# AST1060 register map
File version: 1.0
CPU: CM4 r0p1, little endian, MPU, FPU, 4 interrupt priority bits, 256 interrupts
Registers are 32-bit, read-write, reset 0x0 unless marked. A register's access mark holds for its fields unless they carry their own. Offsets are from the block's base; [hi:lo] are bit positions; {n}, {i} and the like mark numbered series; 'fields as' and 'values as' point back to an identical list.

## i2c
Base 0x7E7B0080
Same registers: i2c{n} {0x7E7B0080+0x80*n} (n=1..13)
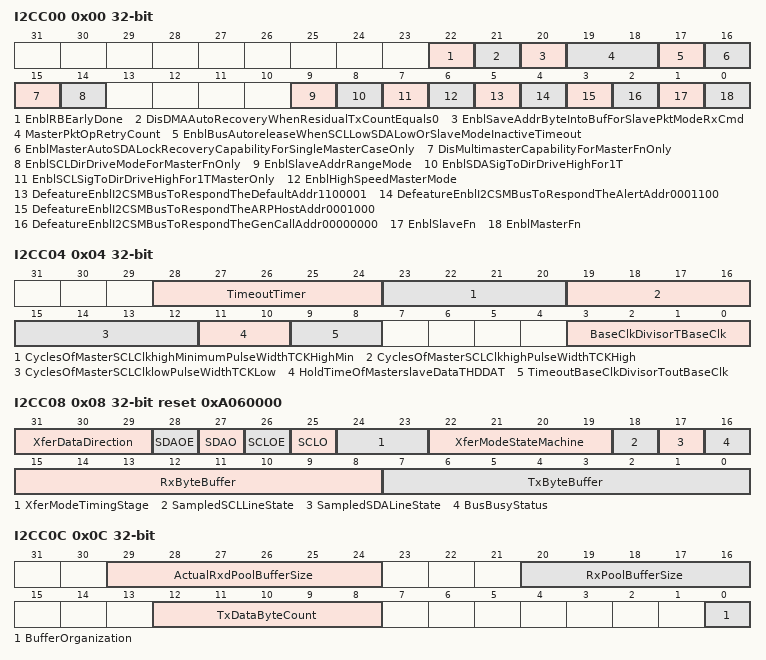
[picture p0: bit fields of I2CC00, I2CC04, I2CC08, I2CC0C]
0x00 I2CC00 (reset mask 0x3FC3FF) — Master/Slave Function Control Register
  [22] EnblRBEarlyDone — Enable RB early done
  [21] DisDMAAutoRecoveryWhenResidualTxCountEquals0 — DisableDMA AutoRecovery when residual Tx Count equals 0
  [20] EnblSaveAddrByteIntoBufForSlavePktModeRxCmd — Enable save address byte into buffer for Slave Packet mode receive command
  [19:18] MasterPktOpRetryCount — Master packet operation retry count
  [17] EnblBusAutoreleaseWhenSCLLowSDALowOrSlaveModeInactiveTimeout — Enable bus auto-release when SCL low, SDA low, or slave mode inactive timeout
  [16] EnblMasterAutoSDALockRecoveryCapabilityForSingleMasterCaseOnly — Enable master auto SDA lock recovery capability (for single master case only)
  [15] DisMultimasterCapabilityForMasterFnOnly — Disable multi-master capability (for master function only)
  [14] EnblSCLDirDriveModeForMasterFnOnly — Enable SCL direct drive mode (for master function only)
  [9] EnblSlaveAddrRangeMode — Enable slave address range mode
  [8] EnblSDASigToDirDriveHighFor1T — Enable SDA signal to direct drive high for 1T
  [7] EnblSCLSigToDirDriveHighFor1TMasterOnly — Enable SCL signal to direct drive high for 1T (Master Only)
  [6] EnblHighSpeedMasterMode — Enable High Speed master mode
  [5] DefeatureEnblI2CSMBusToRespondTheDefaultAddr1100001 — defeatureEnable I2C/SMBus to respond the Default Address (1100_001)
  [4] DefeatureEnblI2CSMBusToRespondTheAlertAddr0001100 — defeatureEnable I2C/SMBus to respond the Alert Address (0001_100)
  [3] DefeatureEnblI2CSMBusToRespondTheARPHostAddr0001000 — defeatureEnable I2C/SMBus to respond the ARP Host Address (0001_000)
  [2] DefeatureEnblI2CSMBusToRespondTheGenCallAddr00000000 — defeatureEnable I2C/SMBus to respond the General Call Address (0000_0000)
  [1] EnblSlaveFn — Enable slave function
  [0] EnblMasterFn — Enable master function
0x04 I2CC04 — Master/Slave Clock and AC Timing Control Register \#1
  [28:24] TimeoutTimer
  [23:20] CyclesOfMasterSCLClkhighMinimumPulseWidthTCKHighMin — Cycles of master SCL clock-high minimum pulse width (tCKHighMin)
  [19:16] CyclesOfMasterSCLClkhighPulseWidthTCKHigh — Cycles of master SCL clock-high pulse width (tCKHigh)
  [15:12] CyclesOfMasterSCLClklowPulseWidthTCKLow — Cycles of master SCL clock-low pulse width (tCKLow)
  [11:10] HoldTimeOfMasterslaveDataTHDDAT
  [9:8] TimeoutBaseClkDivisorToutBaseClk — Timeout base clock divisor (toutBaseClk)
  [3:0] BaseClkDivisorTBaseClk — Base Clock divisor (tBaseClk)
0x08 I2CC08 reset 0xA060000 — Master/Slave Transmit/Receive Byte Buffer Register
  [31:29] XferDataDirection ro — Transfer Data Direction
  [28] SDAOE ro
  [27] SDAO ro
  [26] SCLOE ro
  [25] SCLO ro
  [24:23] XferModeTimingStage ro — Transfer Mode Timing Stage
  [22:19] XferModeStateMachine ro — Transfer Mode State Machine
  [18] SampledSCLLineState ro
  [17] SampledSDALineState ro
  [16] BusBusyStatus ro
  [15:8] RxByteBuffer ro — Receive Byte Buffer
  [7:0] TxByteBuffer — Transmit Byte Buffer
0x0C I2CC0C — Master/Slave Pool Buffer Control Register
  [29:24] ActualRxdPoolBufferSize — Actual Received Pool Buffer Size
  [20:16] RxPoolBufferSize — Receive Pool Buffer Size
  [12:8] TxDataByteCount — Transmit Data Byte Count
  [0] BufferOrganization
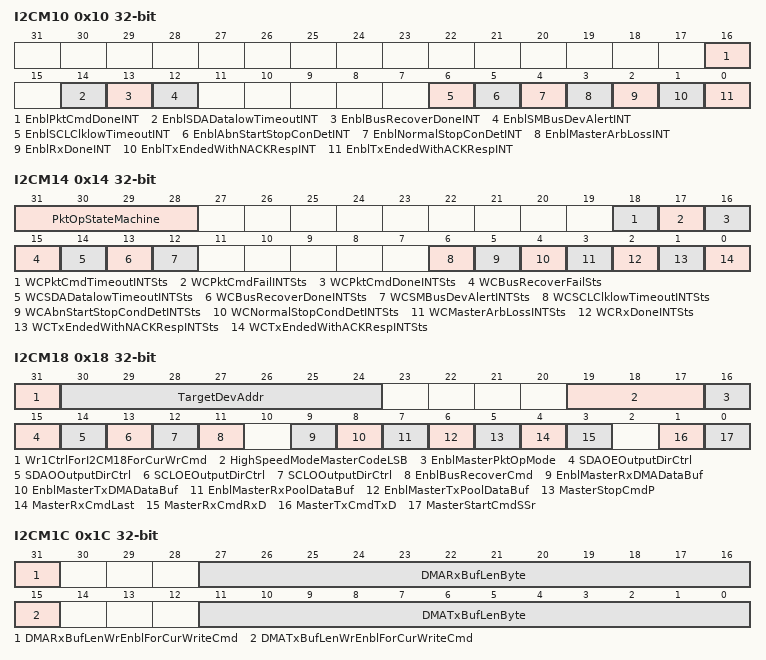
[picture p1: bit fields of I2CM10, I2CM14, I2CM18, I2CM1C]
0x10 I2CM10 — Master Interrupt Control Register
  [16] EnblPktCmdDoneINT — Enable Packet command done interrupt
  [14] EnblSDADatalowTimeoutINT — Enable SDA data-low timeout interrupt
  [13] EnblBusRecoverDoneINT — Enable Bus Recover Done interrupt
  [12] EnblSMBusDevAlertINT — Enable SMBus Device Alert interrupt
  [6] EnblSCLClklowTimeoutINT — Enable SCL clock-low timeout interrupt
  [5] EnblAbnStartStopConDetINT — Enable abnormal Start/Stop condition detection interrupt
  [4] EnblNormalStopConDetINT — Enable normal Stop condition detection interrupt
  [3] EnblMasterArbLossINT — Enable master arbitration loss interrupt
  [2] EnblRxDoneINT — Enable Receive Done interrupt
  [1] EnblTxEndedWithNACKRespINT — Enable Transmit ended with NACK response interrupt
  [0] EnblTxEndedWithACKRespINT — Enable Transmit ended with ACK response interrupt
0x14 I2CM14 — Master Interrupt Status Register
  [31:28] PktOpStateMachine ro — Packet Operation State Machine
  [18] WCPktCmdTimeoutINTSts — (WC) newverPacket command timeout interrupt status
  [17] WCPktCmdFailINTSts — (WC) newverPacket command fail interrupt status
  [16] WCPktCmdDoneINTSts — (WC) newverPacket command done interrupt status
  [15] WCBusRecoverFailSts — (WC) newverBus Recover Fail status
  [14] WCSDADatalowTimeoutINTSts — (WC) SDA data-low timeout interrupt status
  [13] WCBusRecoverDoneINTSts — (WC) Bus Recover Done interrupt status
  [12] WCSMBusDevAlertINTSts — (WC) SMBus Device Alert interrupt status
  [6] WCSCLClklowTimeoutINTSts — (WC) SCL clock-low timeout interrupt status
  [5] WCAbnStartStopCondDetINTSts — (WC) Abnormal Start/Stop Condition Detection interrupt status
  [4] WCNormalStopCondDetINTSts — (WC) Normal Stop Condition Detection interrupt status
  [3] WCMasterArbLossINTSts — (WC) Master Arbitration Loss interrupt status
  [2] WCRxDoneINTSts — (WC) Receive Done interrupt status
  [1] WCTxEndedWithNACKRespINTSts — (WC) Transmit ended with NACK response interrupt status
  [0] WCTxEndedWithACKRespINTSts — (WC) Transmit ended with ACK response interrupt status
0x18 I2CM18 — Master Command/Status Register
  [31] Wr1CtrlForI2CM18ForCurWrCmd — Write '1' control for I2CM18 for current write command
  [30:24] TargetDevAddr — Target device address
  [19:17] HighSpeedModeMasterCodeLSB
  [16] EnblMasterPktOpMode — Enable master Packet operation mode
  [15] SDAOEOutputDirCtrl — SDA_OE output direct control
  [14] SDAOOutputDirCtrl — SDA_O output direct control
  [13] SCLOEOutputDirCtrl — SCL_OE output direct control
  [12] SCLOOutputDirCtrl — SCL_O output direct control
  [11] EnblBusRecoverCmd — Enable Bus Recover Command
  [9] EnblMasterRxDMADataBuf — Enable Master Rx DMA Data buffer
  [8] EnblMasterTxDMADataBuf — Enable Master Tx DMA Data buffer
  [7] EnblMasterRxPoolDataBuf — Enable Master Rx Pool Data buffer
  [6] EnblMasterTxPoolDataBuf — Enable Master Tx Pool Data buffer
  [5] MasterStopCmdP — Master Stop Command (P)
  [4] MasterRxCmdLast — Master Receive Command Last
  [3] MasterRxCmdRxD — Master Receive Command (RxD)
  [1] MasterTxCmdTxD — Master Transmit Command (TxD)
  [0] MasterStartCmdSSr — Master Start Command (S/Sr)
0x1C I2CM1C — ewver{Master DMA Transfer Length Register
  [31] DMARxBufLenWrEnblForCurWriteCmd — DMA Rx buffer length write enable for current write command
  [27:16] DMARxBufLenByte — DMA Rx buffer length (Byte)
  [15] DMATxBufLenWrEnblForCurWriteCmd — DMA Tx buffer length write enable for current write command
  [11:0] DMATxBufLenByte — DMA Tx buffer length (Byte)
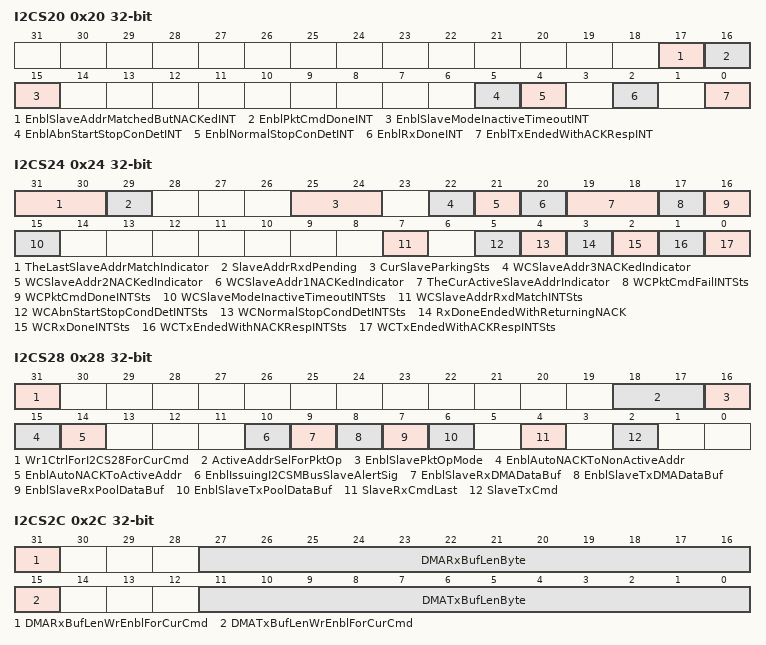
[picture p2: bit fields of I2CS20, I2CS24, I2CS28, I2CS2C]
0x20 I2CS20 — Slave Interrupt Control Register
  [17] EnblSlaveAddrMatchedButNACKedINT — Enable Slave address matched but NACKed interrupt
  [16] EnblPktCmdDoneINT — Enable Packet command done interrupt
  [15] EnblSlaveModeInactiveTimeoutINT — Enable Slave mode inactive timeout interrupt
  [5] EnblAbnStartStopConDetINT — Enable abnormal Start/Stop condition detection interrupt
  [4] EnblNormalStopConDetINT — Enable normal Stop condition detection interrupt
  [2] EnblRxDoneINT — Enable Receive Done interrupt
  [0] EnblTxEndedWithACKRespINT — Enable Transmit ended with ACK response interrupt
0x24 I2CS24 — Slave Interrupt Status Register
  [31:30] TheLastSlaveAddrMatchIndicator ro — The Last Slave address match indicator
  [29] SlaveAddrRxdPending ro — Slave Address Received Pending
  [25:24] CurSlaveParkingSts ro — Current Slave parking status
  [22] WCSlaveAddr3NACKedIndicator — (WC) newverSlave address3 NACKed indicator
  [21] WCSlaveAddr2NACKedIndicator — (WC) newverSlave address2 NACKed indicator
  [20] WCSlaveAddr1NACKedIndicator — (WC) newverSlave address1 NACKed indicator
  [19:18] TheCurActiveSlaveAddrIndicator ro — The current active Slave address indicator
  [17] WCPktCmdFailINTSts — (WC) newverPacket command fail interrupt status
  [16] WCPktCmdDoneINTSts — (WC) newverPacket command done interrupt status
  [15] WCSlaveModeInactiveTimeoutINTSts — (WC) Slave mode inactive timeout interrupt status
  [7] WCSlaveAddrRxdMatchINTSts — (WC) Slave Address Received Match interrupt status
  [5] WCAbnStartStopCondDetINTSts — (WC) Abnormal Start/Stop Condition Detection interrupt status
  [4] WCNormalStopCondDetINTSts — (WC) Normal Stop Condition Detection interrupt status
  [3] RxDoneEndedWithReturningNACK ro — Receive Done ended with returning NACK
  [2] WCRxDoneINTSts — (WC) Receive Done interrupt status
  [1] WCTxEndedWithNACKRespINTSts — (WC) Transmit ended with NACK response interrupt status
  [0] WCTxEndedWithACKRespINTSts — (WC) Transmit ended with ACK response interrupt status
0x28 I2CS28 — Slave Command/Status Register
  [31] Wr1CtrlForI2CS28ForCurCmd — Write '1' control for I2CS28 for current command
  [18:17] ActiveAddrSelForPktOp — Active address selection for Packet operation
  [16] EnblSlavePktOpMode — Enable slave Packet operation mode
  [15] EnblAutoNACKToNonActiveAddr — Enable Auto NACK to Non-Active address
  [14] EnblAutoNACKToActiveAddr — Enable Auto NACK to Active address
  [10] EnblIssuingI2CSMBusSlaveAlertSig — Enable issuing I2C/SMBus Slave Alert signal
  [9] EnblSlaveRxDMADataBuf — Enable Slave Rx DMA Data buffer
  [8] EnblSlaveTxDMADataBuf — Enable Slave Tx DMA Data buffer
  [7] EnblSlaveRxPoolDataBuf — Enable Slave Rx Pool Data buffer
  [6] EnblSlaveTxPoolDataBuf — Enable Slave Tx Pool Data buffer
  [4] SlaveRxCmdLast — Slave Receive Command Last
  [2] SlaveTxCmd — Slave Transmit Command
0x2C I2CS2C — ewver{Slave DMA Transfer Length Register
  [31] DMARxBufLenWrEnblForCurCmd — DMA Rx buffer length write enable for current command
  [27:16] DMARxBufLenByte — DMA Rx buffer length (Byte)
  [15] DMATxBufLenWrEnblForCurCmd — DMA Tx buffer length write enable for current command
  [11:0] DMATxBufLenByte — DMA Tx buffer length (Byte)
0x30 I2CM30 — ewver{Master DMA Mode Tx Buffer Base Address
  [30:0] SDRAMDMABufferBaseAddr — SDRAM DMA Buffer Base Address
0x34 I2CM34 — ewver{Master DMA Mode Rx Buffer Base Address
  [30:0] SDRAMDMABufferBaseAddr1 — SDRAM DMA Buffer Base Address
0x38 I2CS38 — ewver{Slave~ DMA Mode Tx Buffer Base Address
  [30:0] SDRAMDMABufferBaseAddr2 — SDRAM DMA Buffer Base Address
0x3C I2CS3C — ewver{Slave~ DMA Mode Rx Buffer Base Address
  [30:0] SDRAMDMABufferBaseAddr3 — SDRAM DMA Buffer Base Address
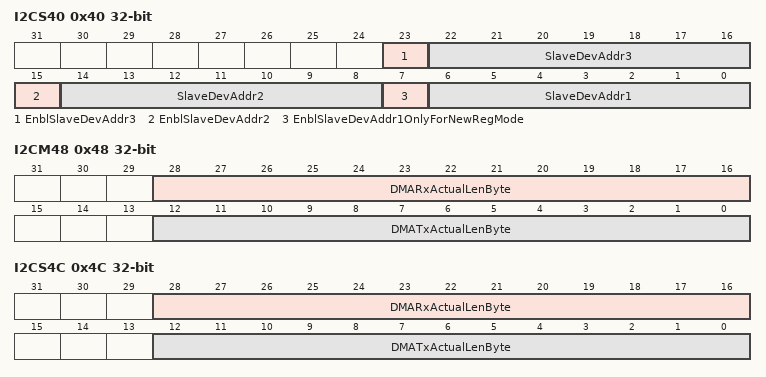
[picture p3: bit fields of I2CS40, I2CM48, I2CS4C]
0x40 I2CS40 — Slave Device Address Register
  [23] EnblSlaveDevAddr3 — Enable Slave Device Address3
  [22:16] SlaveDevAddr3 — Slave Device Address3
  [15] EnblSlaveDevAddr2 — Enable Slave Device Address2
  [14:8] SlaveDevAddr2 — Slave Device Address2
  [7] EnblSlaveDevAddr1OnlyForNewRegMode — Enable Slave Device Address1 (only for New Register mode)
  [6:0] SlaveDevAddr1 — Slave Device Address1
0x48 I2CM48 — Master DMA Length Status Register
  [28:16] DMARxActualLenByte — DMA Rx actual length (Byte)
  [12:0] DMATxActualLenByte — DMA Tx actual length (Byte)
0x4C I2CS4C — Slave DMA Length Status Register
  fields as I2CM48
0x50 I2CC50 — Current DMA Operating Address Status
  [31:0] CurDMAOperatingAddrCounter ro — Current DMA Operating Address Counter
0x54 I2CC54 — Current DMA Operating Length Status
  [11:0] CurDMAOperatingLengthCounter ro — Current DMA Operating Length Counter
